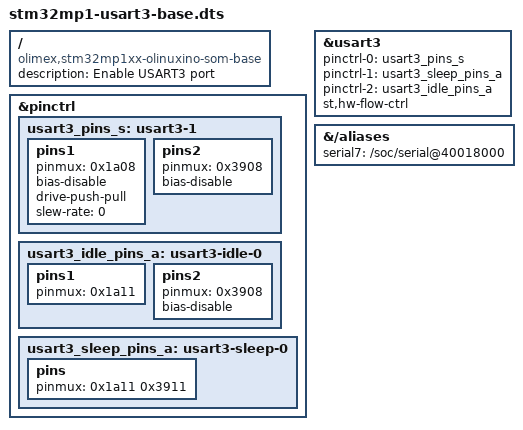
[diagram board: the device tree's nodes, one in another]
/dts-v1/;
/plugin/;
/ {
	compatible = "olimex,stm32mp1xx-olinuxino-som-base";
	description = "Enable USART3 port";

	fragment@0 {
		target = <&pinctrl>;
		__overlay__ {
			usart3_pins_s: usart3-1 {
				pins1 {
					pinmux = <0x1a08>;/* usart3_TX PB10 AF7 */
					bias-disable;
					drive-push-pull;
					slew-rate = <0>;
				};
				pins2 {
					pinmux = <0x3908>; /* usart3_RX PD9 AF7 */
					bias-disable;
				};
			};
			usart3_idle_pins_a: usart3-idle-0 {
				pins1 {
					pinmux = <0x1a11>; /* USART3_TX */
				};
				pins2 {
					pinmux = <0x3908>; /* USART3_RX */
					bias-disable;
				};
			};
			usart3_sleep_pins_a: usart3-sleep-0 {
				pins {
					pinmux = <0x1a11 0x3911>;
				};
			};
		};

	};

	fragment@1 {
		target = <&usart3>;
		__overlay__ {
			pinctrl-names = "default";
			pinctrl-0 = <&usart3_pins_s>;
			pinctrl-1 = <&usart3_sleep_pins_a>;
			pinctrl-2 = <&usart3_idle_pins_a>;
			st,hw-flow-ctrl;
			status = "okay";
		};
	};

	fragment@2 {
		target-path = "/aliases";
		__overlay__ {
			serial7 = "/soc/serial@40018000";
		};
	};
};

